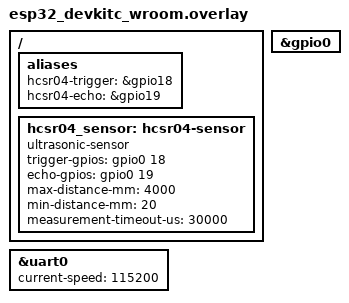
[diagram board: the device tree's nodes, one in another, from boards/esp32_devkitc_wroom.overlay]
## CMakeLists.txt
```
cmake_minimum_required(VERSION 3.20.0)
find_package(Zephyr REQUIRED HINTS $ENV{ZEPHYR_BASE})
project(bthome_ultrasonic)

target_sources(app PRIVATE src/main.c src/hcsr04.c)
```

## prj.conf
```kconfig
# BTHome Ultrasonic Distance Sensor - Common Configuration
# Platform-specific settings are in boards/*.conf files

# Common Bluetooth Low Energy Configuration
CONFIG_BT=y
CONFIG_BT_PERIPHERAL=y
CONFIG_BT_BROADCASTER=y

# Common GPIO support for HC-SR04 sensor
CONFIG_GPIO=y

# Common logging configuration
CONFIG_LOG=y
CONFIG_LOG_DEFAULT_LEVEL=4
CONFIG_PRINTK=y
CONFIG_CONSOLE=y
CONFIG_UART_CONSOLE=y
CONFIG_LOG_BACKEND_UART=y
CONFIG_LOG_MODE_IMMEDIATE=y

# Common system configuration
CONFIG_MAIN_STACK_SIZE=4096
CONFIG_SYSTEM_WORKQUEUE_STACK_SIZE=2048
```

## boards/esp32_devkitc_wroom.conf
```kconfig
# ESP32-specific Configuration for BTHome Ultrasonic Sensor

# Bluetooth configuration for ESP32 (uses NimBLE stack)
CONFIG_BT_NIMBLE=y
CONFIG_BT_NIMBLE_GAP_DEVICE_NAME="BTHome Ultrasonic ESP32"
CONFIG_BT_NIMBLE_MAX_CONNECTIONS=1
CONFIG_BT_NIMBLE_ROLE_BROADCASTER=y
CONFIG_BT_NIMBLE_ROLE_PERIPHERAL=y

# Disable unnecessary BLE features for power savings
CONFIG_BT_NIMBLE_ROLE_CENTRAL=n
CONFIG_BT_NIMBLE_ROLE_OBSERVER=n
CONFIG_BT_NIMBLE_EXT_ADV=n

# GPIO support for HC-SR04 sensor
CONFIG_GPIO=y

# ESP32-specific timer support for precise measurements
CONFIG_COUNTER=y
CONFIG_ESP32_TIMER=y

# ESP32-specific logging via UART
CONFIG_LOG=y
CONFIG_LOG_DEFAULT_LEVEL=3
CONFIG_UART_CONSOLE=y
CONFIG_CONSOLE=y

# ESP32 system configuration
CONFIG_MAIN_STACK_SIZE=4096
CONFIG_SYSTEM_WORKQUEUE_STACK_SIZE=2048

# ESP32 memory optimization
CONFIG_BT_NIMBLE_MSYS_1_BLOCK_COUNT=12
CONFIG_BT_NIMBLE_MSYS_1_BLOCK_SIZE=292
```

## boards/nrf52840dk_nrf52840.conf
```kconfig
# nRF52840-specific Configuration for BTHome Ultrasonic Sensor

# Nordic SoftDevice Bluetooth configuration
CONFIG_BT_DEVICE_NAME="BTHome Ultrasonic nRF52"

# nRF52840-specific BLE optimizations
CONFIG_BT_CTLR_TX_PWR_PLUS_8=y

# nRF52840 GPIO configuration
CONFIG_GPIO=y

# nRF52840-specific timing functions
CONFIG_TIMING_FUNCTIONS=y

# nRF52840 system configuration  
CONFIG_MAIN_STACK_SIZE=2048
CONFIG_SYSTEM_WORKQUEUE_STACK_SIZE=2048
```

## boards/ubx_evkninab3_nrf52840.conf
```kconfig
# NINA-B3 (nRF52840) specific Configuration for BTHome Ultrasonic Sensor

# Nordic SoftDevice Bluetooth configuration
CONFIG_BT_DEVICE_NAME="BTHome Ultrasonic NINA-B3"

# nRF52840-specific BLE optimizations
CONFIG_BT_CTLR_TX_PWR_PLUS_8=y

# NINA-B3 GPIO configuration
CONFIG_GPIO=y

# nRF52840-specific timing functions
CONFIG_TIMING_FUNCTIONS=y

# NINA-B3 system configuration  
CONFIG_MAIN_STACK_SIZE=2048
CONFIG_SYSTEM_WORKQUEUE_STACK_SIZE=2048
```

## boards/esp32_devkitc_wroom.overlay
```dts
/*
 * Device Tree Overlay for BTHome Ultrasonic Sensor on ESP32 DevKitC
 * Configures GPIO pins for HC-SR04 sensor
 */

/ {
    aliases {
        /* HC-SR04 sensor pin assignments for ESP32 */
        hcsr04-trigger = &gpio18;  /* GPIO18 - Trigger pin */
        hcsr04-echo = &gpio19;     /* GPIO19 - Echo pin */
    };
    
    /* HC-SR04 sensor node for ESP32 */
    hcsr04_sensor: hcsr04-sensor {
        compatible = "ultrasonic-sensor";
        status = "okay";
        
        /* GPIO pin specifications */
        trigger-gpios = <&gpio0 18 GPIO_ACTIVE_HIGH>;
        echo-gpios = <&gpio0 19 GPIO_ACTIVE_HIGH>;
        
        /* Sensor specifications */
        max-distance-mm = <4000>;
        min-distance-mm = <20>;
        measurement-timeout-us = <30000>;
    };
};

/* Enable GPIO controller */
&gpio0 {
    status = "okay";
};

/* Configure UART for debugging */
&uart0 {
    status = "okay";
    current-speed = <115200>;
};
```

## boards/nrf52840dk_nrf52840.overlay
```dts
/*
 * Device Tree Overlay for BTHome Ultrasonic Sensor on nRF52840-DK
 * Minimal overlay - GPIO configuration is done in code
 */

/* Configure GPIO0 for sensor pins */
&gpio0 {
    status = "okay";
};
```

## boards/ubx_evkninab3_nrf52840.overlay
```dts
/*
 * Device Tree Overlay for BTHome Ultrasonic Sensor on u-blox EVK-NINA-B3
 * Configures GPIO pins for HC-SR04 sensor using dedicated free pins
 */

/ {
    aliases {
        /* HC-SR04 sensor pin assignments for NINA-B3 */
        /* Use P0.08 for trigger and P0.06 for echo - both are free GPIO pins */
        hcsr04-trigger = &gpio0;
        hcsr04-echo = &gpio0;
    };
};

/* Enable GPIO controller */
&gpio0 {
    status = "okay";
};
```

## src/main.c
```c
/*
 * BTHome Ultrasonic Distance Sensor Application
 * Based on BTHome v2 protocol for Home Assistant integration
 * Copyright (c) 2024
 * SPDX-License-Identifier: Apache-2.0
 */

#include <zephyr/kernel.h>
#include <zephyr/device.h>
#include <zephyr/drivers/gpio.h>
#include <zephyr/bluetooth/bluetooth.h>
#include <zephyr/bluetooth/gap.h>
#include <zephyr/sys/byteorder.h>
#include <zephyr/logging/log.h>
#include "hcsr04.h"

LOG_MODULE_REGISTER(bthome_ultrasonic, LOG_LEVEL_INF);

/* BTHome service UUID: 0xFCD2 */
#define BTHOME_SERVICE_UUID         0xFCD2

/* BTHome object IDs */
#define BTHOME_OBJECT_DISTANCE_MM   0x40    /* Distance in millimeters */

/* Measurement interval */
#define MEASUREMENT_INTERVAL_MS     5000    /* 5 seconds */

/* Platform-specific HC-SR04 GPIO pin definitions */
#if defined(CONFIG_BOARD_NRF52840DK_NRF52840) || defined(CONFIG_BOARD_UBX_EVKNINAB3_NRF52840)
    /* Nordic boards: Use dedicated free GPIO pins */
    #define TRIGGER_PIN         8   /* P0.08 */
    #define ECHO_PIN            6   /* P0.06 */
    #define GPIO_DEVICE         DEVICE_DT_GET(DT_NODELABEL(gpio0))
#elif defined(CONFIG_BOARD_ESP32_DEVKITC_WROOM)
    /* ESP32: Use GPIO18 and GPIO19 */
    #define TRIGGER_PIN         18
    #define ECHO_PIN            19  
    #define GPIO_DEVICE         DEVICE_DT_GET(DT_NODELABEL(gpio0))
#else
    #error "Unsupported board. Please add GPIO pin definitions for your board."
#endif

/* HC-SR04 sensor configuration */
static const struct hcsr04_config sensor_config = {
    .trigger_gpio = {.port = GPIO_DEVICE, .pin = TRIGGER_PIN, .dt_flags = GPIO_ACTIVE_HIGH},
    .echo_gpio = {.port = GPIO_DEVICE, .pin = ECHO_PIN, .dt_flags = GPIO_ACTIVE_HIGH},
    .max_distance_mm = 4000,    /* 4 meters maximum range */
    .timeout_us = 30000,        /* 30ms timeout */
};

static struct hcsr04_data sensor_data;

/* Bluetooth advertisement data */
static struct bt_data ad[] = {
    BT_DATA_BYTES(BT_DATA_FLAGS, (BT_LE_AD_GENERAL | BT_LE_AD_NO_BREDR)),
    BT_DATA_BYTES(BT_DATA_UUID16_ALL, 0xD2, 0xFC),  /* BTHome service UUID */
    BT_DATA(BT_DATA_SVC_DATA16, NULL, 0),  /* Will be updated with sensor data */
};

/* BTHome service data buffer */
static uint8_t bthome_data[10];

/**
 * @brief Create BTHome advertisement packet with distance measurement
 * 
 * @param distance_mm Distance in millimeters
 * @return Length of the created packet
 */
static uint8_t create_bthome_packet(uint16_t distance_mm)
{
    uint8_t *data = bthome_data;
    uint8_t len = 0;
    
    /* BTHome service UUID (little endian) */
    data[len++] = 0xD2;
    data[len++] = 0xFC;
    
    /* BTHome v2 info byte: 0x40 = encrypted=false, bindkey_verified=false, version=2 */
    data[len++] = 0x40;
    
    /* Distance object: Object ID (0x40) + 2 bytes distance in mm (little endian) */
    data[len++] = BTHOME_OBJECT_DISTANCE_MM;
    data[len++] = (uint8_t)(distance_mm & 0xFF);        /* Low byte */
    data[len++] = (uint8_t)((distance_mm >> 8) & 0xFF); /* High byte */
    
    return len;
}

/**
 * @brief Update advertisement with new distance measurement
 * 
 * @param distance_mm Distance in millimeters
 */
static void update_advertisement(uint16_t distance_mm)
{
    int err;
    uint8_t data_len;
    
    /* Create BTHome packet */
    data_len = create_bthome_packet(distance_mm);
    
    /* Update service data in advertisement */
    ad[2].data = bthome_data;
    ad[2].data_len = data_len;
    
    /* Stop previous advertising */
    err = bt_le_adv_stop();
    if (err && err != -EALREADY) {
        LOG_ERR("Failed to stop advertising: %d", err);
        return;
    }
    
    /* Start advertising with updated data */
    err = bt_le_adv_start(BT_LE_ADV_NCONN, ad, ARRAY_SIZE(ad), NULL, 0);
    if (err) {
        LOG_ERR("Failed to start advertising: %d", err);
        return;
    }
    
    if (distance_mm == 0xFFFF) {
        LOG_INF("📡 Advertising ERROR: No measurement available");
    } else {
        LOG_INF("📡 Advertising distance: %u mm (%.1f cm)", distance_mm, distance_mm / 10.0);
    }
}

/**
 * @brief Bluetooth ready callback
 */
static void bt_ready(int err)
{
    if (err) {
        LOG_ERR("❌ Bluetooth init failed: %d", err);
        return;
    }
    
    LOG_INF("✅ Bluetooth initialized successfully");
    LOG_INF("📡 Starting BTHome advertisement...");
    LOG_INF("🔑 Service UUID: 0xFCD2 (BTHome v2)");
    
    /* Start initial advertisement with zero distance */
    update_advertisement(0);
}

/**
 * @brief Main measurement and advertisement loop
 */
static void measurement_thread(void)
{
    int32_t distance;
    
    LOG_INF("🚀 Starting measurement loop...");
    
    while (1) {
        LOG_DBG("📏 Performing distance measurement...");
        
        /* Perform distance measurement */
        distance = hcsr04_measure_distance(&sensor_config, &sensor_data);
        
        if (distance > 0) {
            /* Valid measurement - update advertisement */
            update_advertisement((uint16_t)distance);
            LOG_INF("✅ Distance measured: %d mm (%.1f cm)", distance, distance / 10.0);
        } else {
            /* Invalid measurement - log error but continue */
            switch (distance) {
                case -ETIMEDOUT:
                    LOG_WRN("⏰ Measurement timeout - no object detected");
                    break;
                case -ERANGE:
                    LOG_WRN("📐 Distance out of range");
                    break;
                case -EBUSY:
                    LOG_WRN("🔒 Sensor busy - measurement skipped");
                    break;
                default:
                    LOG_WRN("❌ Measurement failed with error: %d", distance);
                    break;
            }
            
            /* Send error value (0xFFFF = no measurement) */
            update_advertisement(0xFFFF);
        }
        
        /* Wait for next measurement */
        LOG_DBG("⏱️  Waiting %d seconds for next measurement...", MEASUREMENT_INTERVAL_MS / 1000);
        k_sleep(K_MSEC(MEASUREMENT_INTERVAL_MS));
    }
}

/* Define measurement thread */
K_THREAD_DEFINE(measurement_tid, 1024, measurement_thread, NULL, NULL, NULL, 7, 0, 0);

int main(void)
{
    int err;
    
    LOG_INF("🌟 BTHome Ultrasonic Distance Sensor starting...");
    LOG_INF("📋 Board: %s", CONFIG_BOARD);
    
    /* Check if GPIO device is ready */
    if (!device_is_ready(GPIO_DEVICE)) {
        LOG_ERR("❌ GPIO device not ready");
        return -ENODEV;
    }
    
    LOG_INF("🔧 GPIO Configuration:");
#if defined(CONFIG_BOARD_NRF52840DK_NRF52840) || defined(CONFIG_BOARD_UBX_EVKNINAB3_NRF52840)
    LOG_INF("   📌 Trigger Pin: P0.%02d", TRIGGER_PIN);
    LOG_INF("   📌 Echo Pin:    P0.%02d", ECHO_PIN);
#elif defined(CONFIG_BOARD_ESP32_DEVKITC_WROOM)
    LOG_INF("   📌 Trigger Pin: GPIO%d", TRIGGER_PIN);
    LOG_INF("   📌 Echo Pin:    GPIO%d", ECHO_PIN);
#endif
    
    /* Initialize HC-SR04 sensor */
    LOG_INF("🔧 Initializing HC-SR04 sensor...");
    err = hcsr04_init(&sensor_config, &sensor_data);
    if (err) {
        LOG_ERR("❌ Failed to initialize HC-SR04 sensor: %d", err);
        return err;
    }
    LOG_INF("✅ HC-SR04 sensor initialized successfully");
    
    /* Initialize Bluetooth */
    LOG_INF("📡 Initializing Bluetooth...");
    err = bt_enable(bt_ready);
    if (err) {
        LOG_ERR("❌ Bluetooth init failed: %d", err);
        return err;
    }
    
    LOG_INF("🚀 Application initialized. Starting measurements...");
    LOG_INF("📊 Measurement interval: %d seconds", MEASUREMENT_INTERVAL_MS / 1000);
    LOG_INF("📏 Maximum range: %d mm (%.1f cm)", sensor_config.max_distance_mm, sensor_config.max_distance_mm / 10.0);
    
    /* Main thread handles system events */
    while (1) {
        k_sleep(K_SECONDS(1));
    }
    
    return 0;
}
```

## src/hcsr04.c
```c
/*
 * HC-SR04 Ultrasonic Distance Sensor Driver Implementation
 * Copyright (c) 2024
 * SPDX-License-Identifier: Apache-2.0
 */

#include "hcsr04.h"
#include <zephyr/kernel.h>
#include <zephyr/drivers/gpio.h>
#include <zephyr/sys/time_units.h>
#include <zephyr/logging/log.h>

LOG_MODULE_REGISTER(hcsr04, LOG_LEVEL_INF);

/* HC-SR04 timing constants */
#define TRIGGER_PULSE_US    10      /* Trigger pulse duration in microseconds */
#define ECHO_TIMEOUT_US     30000   /* Echo timeout: 30ms for ~5m max range */
#define SOUND_SPEED_CM_US   58      /* Sound speed: 58 us/cm (round trip) */

static void echo_gpio_callback(const struct device *dev, struct gpio_callback *cb, uint32_t pins)
{
    struct hcsr04_data *data = CONTAINER_OF(cb, struct hcsr04_data, echo_cb);
    const struct hcsr04_config *config = data->config;
    
    /* Get current time in microseconds using kernel ticks */
    uint32_t current_time = k_uptime_get_32() * 1000;  /* Convert ms to us */
    
    /* Check if echo pin is high (start of echo) or low (end of echo) */
    if (gpio_pin_get_dt(&config->echo_gpio)) {
        /* Echo started */
        data->echo_start_time = current_time;
    } else {
        /* Echo ended */
        data->echo_end_time = current_time;
        k_sem_give(&data->measurement_sem);
    }
}

int hcsr04_init(const struct hcsr04_config *config, struct hcsr04_data *data)
{
    int ret;
    
    LOG_INF("🔧 Initializing HC-SR04 ultrasonic sensor...");
    
    /* Store configuration pointer */
    data->config = config;
    
    /* Initialize mutex and semaphore */
    k_mutex_init(&data->lock);
    k_sem_init(&data->measurement_sem, 0, 1);
    
    /* Initialize measurement state */
    data->last_distance_mm = 0;
    data->measurement_valid = false;
    data->echo_start_time = 0;
    data->echo_end_time = 0;
    
    /* Check if GPIO devices are ready */
    if (!gpio_is_ready_dt(&config->trigger_gpio)) {
        LOG_ERR("❌ Trigger GPIO device not ready");
        return -ENODEV;
    }
    
    if (!gpio_is_ready_dt(&config->echo_gpio)) {
        LOG_ERR("❌ Echo GPIO device not ready");
        return -ENODEV;
    }
    
    LOG_DBG("📌 Configuring GPIO pins...");
    
    /* Configure trigger pin as output */
    ret = gpio_pin_configure_dt(&config->trigger_gpio, GPIO_OUTPUT_INACTIVE);
    if (ret < 0) {
        LOG_ERR("❌ Failed to configure trigger GPIO: %d", ret);
        return ret;
    }
    
    /* Configure echo pin as input with pull-down */
    ret = gpio_pin_configure_dt(&config->echo_gpio, GPIO_INPUT | GPIO_PULL_DOWN);
    if (ret < 0) {
        LOG_ERR("❌ Failed to configure echo GPIO: %d", ret);
        return ret;
    }
    
    /* Initialize GPIO callback for echo pin */
    gpio_init_callback(&data->echo_cb, echo_gpio_callback, BIT(config->echo_gpio.pin));
    
    /* Add callback to echo pin - trigger on both edges */
    ret = gpio_add_callback(config->echo_gpio.port, &data->echo_cb);
    if (ret < 0) {
        LOG_ERR("❌ Failed to add GPIO callback: %d", ret);
        return ret;
    }
    
    /* Enable interrupt on echo pin */
    ret = gpio_pin_interrupt_configure_dt(&config->echo_gpio, GPIO_INT_EDGE_BOTH);
    if (ret < 0) {
        LOG_ERR("❌ Failed to configure GPIO interrupt: %d", ret);
        return ret;
    }
    
    LOG_INF("✅ HC-SR04 sensor initialized successfully");
    LOG_INF("📏 Max range: %u mm, Timeout: %u us", config->max_distance_mm, config->timeout_us);
    return 0;
}

int32_t hcsr04_measure_distance(const struct hcsr04_config *config, struct hcsr04_data *data)
{
    int ret;
    uint32_t echo_duration_us;
    uint32_t distance_mm;
    
    /* Lock to ensure only one measurement at a time */
    ret = k_mutex_lock(&data->lock, K_MSEC(100));
    if (ret != 0) {
        LOG_WRN("🔒 Failed to acquire measurement lock");
        return -EBUSY;
    }
    
    /* Reset semaphore */
    k_sem_reset(&data->measurement_sem);
    
    LOG_DBG("📡 Sending 10µs trigger pulse...");
    
    /* Send trigger pulse */
    gpio_pin_set_dt(&config->trigger_gpio, 1);
    k_busy_wait(TRIGGER_PULSE_US);
    gpio_pin_set_dt(&config->trigger_gpio, 0);
    
    LOG_DBG("👂 Waiting for echo response...");
    
    /* Wait for echo response with timeout */
    ret = k_sem_take(&data->measurement_sem, K_USEC(ECHO_TIMEOUT_US));
    if (ret != 0) {
        LOG_WRN("⏰ Echo timeout - no object detected or out of range");
        data->measurement_valid = false;
        k_mutex_unlock(&data->lock);
        return -ETIMEDOUT;
    }
    
    /* Calculate echo duration */
    if (data->echo_end_time > data->echo_start_time) {
        echo_duration_us = data->echo_end_time - data->echo_start_time;
    } else {
        /* Handle timer overflow */
        echo_duration_us = (UINT32_MAX - data->echo_start_time) + data->echo_end_time;
    }
    
    LOG_DBG("⏱️  Echo duration: %u µs", echo_duration_us);
    
    /* Convert to distance in millimeters */
    /* Distance = (echo_time_us * speed_of_sound) / 2 */
    /* Distance_cm = echo_time_us / 58 */
    /* Distance_mm = (echo_time_us * 10) / 58 */
    distance_mm = (echo_duration_us * 10) / SOUND_SPEED_CM_US;
    
    /* Validate measurement range */
    if (distance_mm > config->max_distance_mm || distance_mm < 20) {
        LOG_WRN("📐 Distance out of valid range: %u mm (valid: 20-%u mm)", 
                distance_mm, config->max_distance_mm);
        data->measurement_valid = false;
        k_mutex_unlock(&data->lock);
        return -ERANGE;
    }
    
    /* Store valid measurement */
    data->last_distance_mm = distance_mm;
    data->measurement_valid = true;
    
    k_mutex_unlock(&data->lock);
    
    LOG_DBG("✅ Distance measured: %u mm (%.1f cm, echo: %u µs)", 
            distance_mm, distance_mm / 10.0, echo_duration_us);
    return distance_mm;
}
```

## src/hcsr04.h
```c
/*
 * HC-SR04 Ultrasonic Distance Sensor Driver
 * Copyright (c) 2024
 * SPDX-License-Identifier: Apache-2.0
 */

#ifndef HCSR04_H
#define HCSR04_H

#include <zephyr/kernel.h>
#include <zephyr/drivers/gpio.h>

/**
 * @brief HC-SR04 sensor configuration structure
 */
struct hcsr04_config {
    struct gpio_dt_spec trigger_gpio;
    struct gpio_dt_spec echo_gpio;
    uint32_t max_distance_mm;  /* Maximum measurement distance in mm */
    uint32_t timeout_us;       /* Timeout for echo signal in microseconds */
};

/**
 * @brief HC-SR04 sensor data structure
 */
struct hcsr04_data {
    uint32_t last_distance_mm;
    bool measurement_valid;
    struct k_mutex lock;
    struct gpio_callback echo_cb;
    uint32_t echo_start_time;
    uint32_t echo_end_time;
    struct k_sem measurement_sem;
    const struct hcsr04_config *config;  /* Pointer to configuration */
};

/**
 * @brief Initialize HC-SR04 sensor
 * 
 * @param config Sensor configuration
 * @param data Sensor data structure
 * @return 0 on success, negative error code on failure
 */
int hcsr04_init(const struct hcsr04_config *config, struct hcsr04_data *data);

/**
 * @brief Measure distance with HC-SR04 sensor
 * 
 * @param config Sensor configuration
 * @param data Sensor data structure
 * @return Distance in millimeters, or -1 on error
 */
int32_t hcsr04_measure_distance(const struct hcsr04_config *config, struct hcsr04_data *data);

#endif /* HCSR04_H */
```
